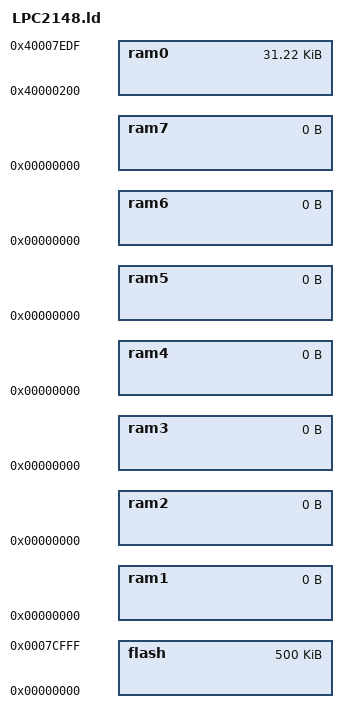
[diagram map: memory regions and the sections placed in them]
/*
    ChibiOS - Copyright (C) 2006..2015 Giovanni Di Sirio.

    This file is part of ChibiOS.

    ChibiOS is free software; you can redistribute it and/or modify
    it under the terms of the GNU General Public License as published by
    the Free Software Foundation; either version 3 of the License, or
    (at your option) any later version.

    ChibiOS is distributed in the hope that it will be useful,
    but WITHOUT ANY WARRANTY; without even the implied warranty of
    MERCHANTABILITY or FITNESS FOR A PARTICULAR PURPOSE.  See the
    GNU General Public License for more details.

    You should have received a copy of the GNU General Public License
    along with this program.  If not, see <http://www.gnu.org/licenses/>.
*/

/*
 * LPC2148 memory setup.
 */
MEMORY
{
    flash : org = 0x00000000, len = 512k - 12k
    ram0  : org = 0x40000200, len = 32k - 0x200 - 288
    ram1  : org = 0x00000000, len = 0
    ram2  : org = 0x00000000, len = 0
    ram3  : org = 0x00000000, len = 0
    ram4  : org = 0x00000000, len = 0
    ram5  : org = 0x00000000, len = 0
    ram6  : org = 0x00000000, len = 0
    ram7  : org = 0x00000000, len = 0
}

/* RAM region to be used for stacks. This stack accommodates the processing
   of all exceptions and interrupts*/
REGION_ALIAS("STACKS_RAM", ram0);

/* RAM region to be used for data segment.*/
REGION_ALIAS("DATA_RAM", ram0);

/* RAM region to be used for BSS segment.*/
REGION_ALIAS("BSS_RAM", ram0);

INCLUDE rules.ld
